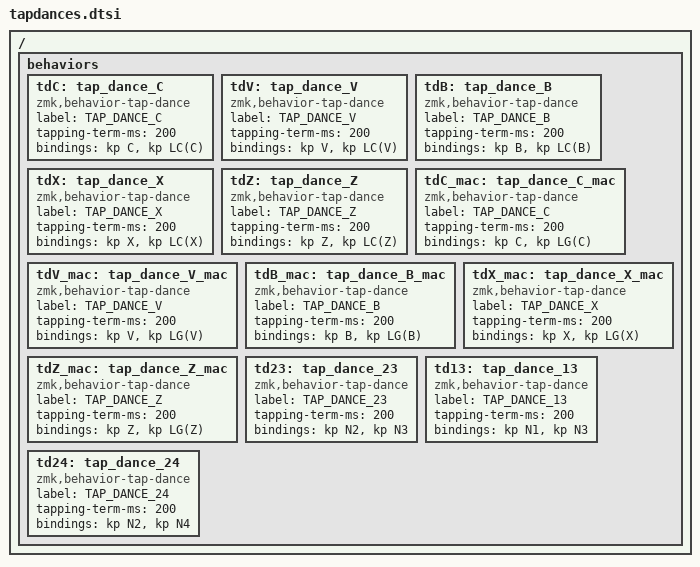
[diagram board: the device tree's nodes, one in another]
#include <behaviors.dtsi>
#include <dt-bindings/zmk/keys.h>
#include "keymap_swedish.h"
/ {
    behaviors {
        /omit-if-no-ref/ tdC: tap_dance_C {
            compatible = "zmk,behavior-tap-dance";
            label = "TAP_DANCE_C";
            #binding-cells = <0>;
            tapping-term-ms = <200>;
            bindings = <&kp C>, <&kp LC(C)>;
        };

        /omit-if-no-ref/ tdV: tap_dance_V {
            compatible = "zmk,behavior-tap-dance";
            label = "TAP_DANCE_V";
            #binding-cells = <0>;
            tapping-term-ms = <200>;
            bindings = <&kp V>, <&kp LC(V)>;
        };

        /omit-if-no-ref/ tdB: tap_dance_B {
            compatible = "zmk,behavior-tap-dance";
            label = "TAP_DANCE_B";
            #binding-cells = <0>;
            tapping-term-ms = <200>;
            bindings = <&kp B>, <&kp LC(B)>;
        };
        
        /omit-if-no-ref/ tdX: tap_dance_X {
            compatible = "zmk,behavior-tap-dance";
            label = "TAP_DANCE_X";
            #binding-cells = <0>;
            tapping-term-ms = <200>;
            bindings = <&kp X>, <&kp LC(X)>;
        };

        /omit-if-no-ref/ tdZ: tap_dance_Z {
            compatible = "zmk,behavior-tap-dance";
            label = "TAP_DANCE_Z";
            #binding-cells = <0>;
            tapping-term-ms = <200>;
            bindings = <&kp Z>, <&kp LC(Z)>;
        };

        /omit-if-no-ref/ tdC_mac: tap_dance_C_mac {
            compatible = "zmk,behavior-tap-dance";
            label = "TAP_DANCE_C";
            #binding-cells = <0>;
            tapping-term-ms = <200>;
            bindings = <&kp C>, <&kp LG(C)>;
        };

        /omit-if-no-ref/ tdV_mac: tap_dance_V_mac {
            compatible = "zmk,behavior-tap-dance";
            label = "TAP_DANCE_V";
            #binding-cells = <0>;
            tapping-term-ms = <200>;
            bindings = <&kp V>, <&kp LG(V)>;
        };

        /omit-if-no-ref/ tdB_mac: tap_dance_B_mac {
            compatible = "zmk,behavior-tap-dance";
            label = "TAP_DANCE_B";
            #binding-cells = <0>;
            tapping-term-ms = <200>;
            bindings = <&kp B>, <&kp LG(B)>;
        };
        
        /omit-if-no-ref/ tdX_mac: tap_dance_X_mac {
            compatible = "zmk,behavior-tap-dance";
            label = "TAP_DANCE_X";
            #binding-cells = <0>;
            tapping-term-ms = <200>;
            bindings = <&kp X>, <&kp LG(X)>;
        };

        /omit-if-no-ref/ tdZ_mac: tap_dance_Z_mac {
            compatible = "zmk,behavior-tap-dance";
            label = "TAP_DANCE_Z";
            #binding-cells = <0>;
            tapping-term-ms = <200>;
            bindings = <&kp Z>, <&kp LG(Z)>;
        };

        /omit-if-no-ref/ td23: tap_dance_23 {
            compatible = "zmk,behavior-tap-dance";
            label = "TAP_DANCE_23";
            #binding-cells = <0>;
            tapping-term-ms = <200>;
            bindings = <&kp N2>, <&kp N3>;
        };

        /omit-if-no-ref/ td13: tap_dance_13 {
            compatible = "zmk,behavior-tap-dance";
            label = "TAP_DANCE_13";
            #binding-cells = <0>;
            tapping-term-ms = <200>;
            bindings = <&kp N1>, <&kp N3>;
        };

        /omit-if-no-ref/ td24: tap_dance_24 {
            compatible = "zmk,behavior-tap-dance";
            label = "TAP_DANCE_24";
            #binding-cells = <0>;
            tapping-term-ms = <200>;
            bindings = <&kp N2>, <&kp N4>;
        };
    };
};
